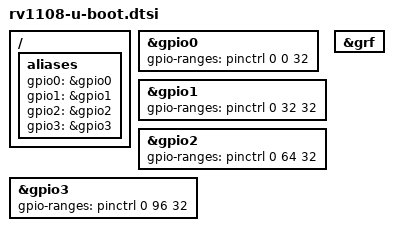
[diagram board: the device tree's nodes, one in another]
// SPDX-License-Identifier: GPL-2.0+
/*
 * Copyright (C) 2019 Jagan Teki <jagan@amarulasolutions.com>
 */

#include "rockchip-u-boot.dtsi"

/ {
	aliases {
		gpio0 = &gpio0;
		gpio1 = &gpio1;
		gpio2 = &gpio2;
		gpio3 = &gpio3;
	};
};

&gpio0 {
	gpio-ranges = <&pinctrl 0 0 32>;
};

&gpio1 {
	gpio-ranges = <&pinctrl 0 32 32>;
};

&gpio2 {
	gpio-ranges = <&pinctrl 0 64 32>;
};

&gpio3 {
	gpio-ranges = <&pinctrl 0 96 32>;
};

&grf {
	bootph-all;
};
